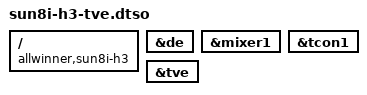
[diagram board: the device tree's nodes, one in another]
// SPDX-License-Identifier: GPL-2.0
/*
 * Composite (CVBS) TV output on H2+/H3.
 *
 * For boards whose DTS does not enable the output itself. It switches on the
 * display engine and the TV encoder; the second mixer and TCON that feed it
 * are already described by the SoC dtsi.
 */
/dts-v1/;
/plugin/;

/ {
	compatible = "allwinner,sun8i-h3";

	fragment@0 {
		target = <&de>;
		__overlay__ {
			status = "okay";
		};
	};

	fragment@1 {
		target = <&mixer1>;
		__overlay__ {
			status = "okay";
		};
	};

	fragment@2 {
		target = <&tcon1>;
		__overlay__ {
			status = "okay";
		};
	};

	fragment@3 {
		target = <&tve>;
		__overlay__ {
			status = "okay";
		};
	};
};
